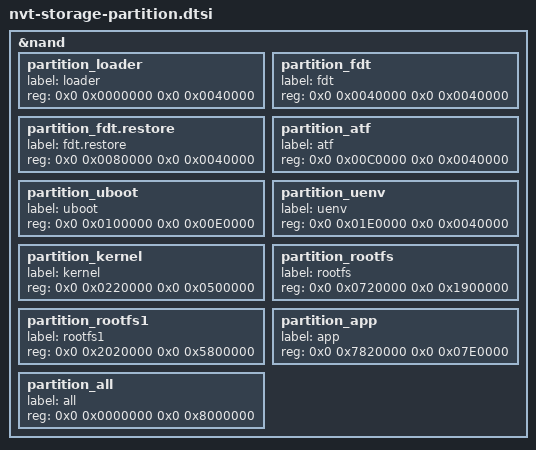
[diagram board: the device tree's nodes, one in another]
/*
 * Novatek Ltd. BSP part of dts
 */

&nand {
    partition_loader {      label = "loader";       reg = <0x0 0x0000000 0x0 0x0040000>; }; /* Fixed */ /* 0.25 MB */
    partition_fdt {         label = "fdt";          reg = <0x0 0x0040000 0x0 0x0040000>; }; /* Fixed */ /* 0.25 MB */
    partition_fdt.restore { label = "fdt.restore";  reg = <0x0 0x0080000 0x0 0x0040000>; }; /* Fixed */ /* 0.25 MB */
    partition_atf {         label = "atf";          reg = <0x0 0x00C0000 0x0 0x0040000>; }; /* 0.25 MB */
    partition_uboot {       label = "uboot";        reg = <0x0 0x0100000 0x0 0x00E0000>; }; /* 0.875 MB */
    partition_uenv {        label = "uenv";         reg = <0x0 0x01E0000 0x0 0x0040000>; }; /* 0.25 MB */
    partition_kernel {      label = "kernel";       reg = <0x0 0x0220000 0x0 0x0500000>; }; /* 5 MB */
    partition_rootfs {      label = "rootfs";       reg = <0x0 0x0720000 0x0 0x1900000>; }; /* 25 MB */
    partition_rootfs1 {     label = "rootfs1";      reg = <0x0 0x2020000 0x0 0x5800000>; }; /* 88 MB */
    partition_app {         label = "app";          reg = <0x0 0x7820000 0x0 0x07E0000>; }; /* app size depneds on hdal/samples/vendor_cfg */ /* 7.875 MB */
    partition_all {         label = "all";          reg = <0x0 0x0000000 0x0 0x8000000>; }; /* 128 MB */
};
